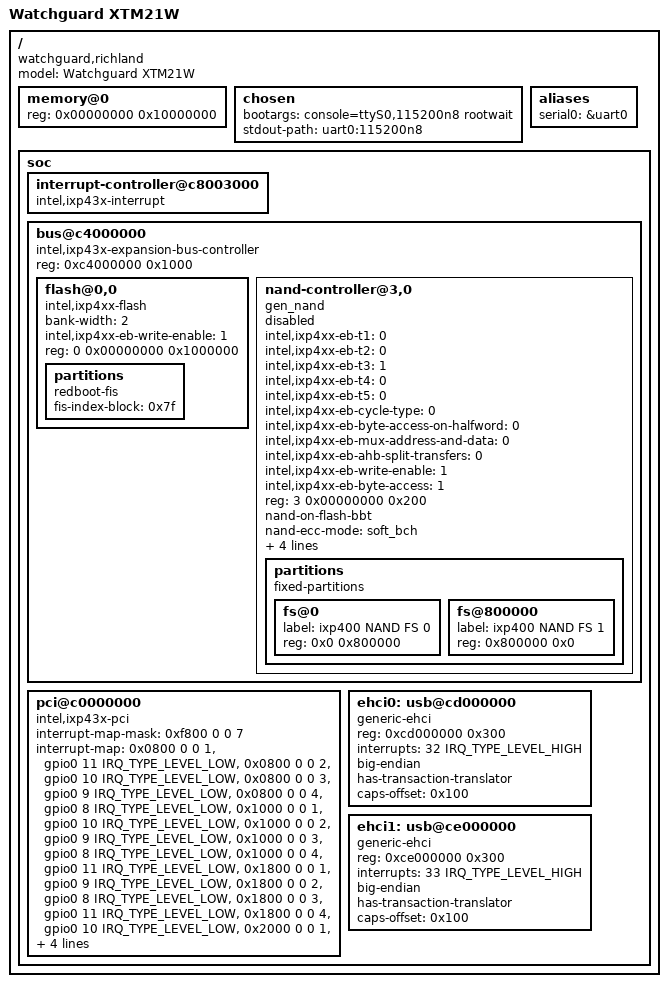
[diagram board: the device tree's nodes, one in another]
// SPDX-License-Identifier: ISC
/*
 * Device Tree file for the Watchguard XTM21-W
 * firewall device.
 */

/dts-v1/;

#include "intel-ixp43x.dtsi"
#include "intel-ixp4xx-reference-design.dtsi"
#include <dt-bindings/input/input.h>

/ {
        model = "Watchguard XTM21W";
        compatible = "watchguard,richland","intel,ixp43x";
        #address-cells = <1>;
        #size-cells = <1>;
        memory@0 {
                /*
                 * The Watchuard XTM21W has 256 MB of memory
                 */
                device_type = "memory";
                reg = <0x00000000 0x10000000>;
        };

        chosen {
                bootargs = "console=ttyS0,115200n8 rootwait";
                stdout-path = "uart0:115200n8";
        };

        aliases {
                serial0 = &uart0;
        };

        soc {
                interrupt-controller@c8003000 {
                        compatible = "intel,ixp43x-interrupt";
                };

                /* TODO: just copied, needs detailed layout for Watchguard Flash and NAND */
                bus@c4000000 {
                        compatible = "intel,ixp43x-expansion-bus-controller", "syscon";
                        /* Uses at least up to 0x230 */
                        reg = <0xc4000000 0x1000>;

                        flash@0,0 {
                                compatible = "intel,ixp4xx-flash", "cfi-flash";
                                bank-width = <2>;
                                /* Enable writes on the expansion bus */
                                intel,ixp4xx-eb-write-enable = <1>;
                                /* 16 MB of Flash mapped in at CS0 */
                                reg = <0 0x00000000 0x1000000>;

                                partitions {
                                        compatible = "redboot-fis";
                                        /* Eraseblock at 0x0fe0000 */
                                        fis-index-block = <0x7f>;
                                };
                        };

                        /* Flash memory defined per-variant */
                        nand-controller@3,0 {
                                /* Some designs have a NAND on CS3 enable it here if present */
                                status = "disabled";

                                /*
                                 * gen_nand needs to be extended and documented to get
                                 * command byte = 1 and address byte = 2 from the device
                                 * tree.
                                 */
                                compatible = "gen_nand";

                                /* Expansion bus set-up */
                                intel,ixp4xx-eb-t1 = <0>;
                                intel,ixp4xx-eb-t2 = <0>;
                                intel,ixp4xx-eb-t3 = <1>; // 1 cycle extra strobe phase
                                intel,ixp4xx-eb-t4 = <0>;
                                intel,ixp4xx-eb-t5 = <0>;
                                intel,ixp4xx-eb-cycle-type = <0>; // Intel cycle type
                                intel,ixp4xx-eb-byte-access-on-halfword = <0>;
                                intel,ixp4xx-eb-mux-address-and-data = <0>;
                                intel,ixp4xx-eb-ahb-split-transfers = <0>;
                                intel,ixp4xx-eb-write-enable = <1>;
                                intel,ixp4xx-eb-byte-access = <1>;

                                /* 512 bytes memory window */
                                reg = <3 0x00000000 0x200>;
                                nand-on-flash-bbt;
                                nand-ecc-mode = "soft_bch";
                                nand-ecc-step-size = <512>;
                                nand-ecc-strength = <4>;
                                nce-gpios = <&gpio0 12 GPIO_ACTIVE_HIGH>; /* NCE */

                                label = "ixp400 NAND";

                                partitions {
                                        compatible = "fixed-partitions";
                                        #address-cells = <1>;
                                        #size-cells = <1>;

                                        fs@0 {
                                                label = "ixp400 NAND FS 0";
                                                reg = <0x0 0x800000>;
                                        };
                                        fs@800000 {
                                                label = "ixp400 NAND FS 1";
                                                reg = <0x800000 0x0>;
                                        };
                                };
                        };
                };

                /* The Linux Kernel Watchguard deployed had the PCI Non-Preftecht Workaround Enabled
                 * So we assume it needed despite the XTM2 being IXP435 ?
                 * PCI: IXP43x Richland silicon detected - PCI Non-Prefetch Workaround Enabled
                 * no difference observed between using compatible ixp42x-pci or ixp43x-pci....
                 * TODO: ixp42x-pci maybe not a good choice, create richland-pci or reduce to 1 slot only as on HW ?
                 */

                pci@c0000000 {
                        compatible = "intel,ixp43x-pci"; /* works wihtout the workaround */
                        status = "ok";

                        /*
                         * Taken from IXDP425 PCI boardfile.
                         * PCI slots on the BIXMB425BD base card.
                         * We have up to 4 slots (IDSEL) with 4 swizzled IRQs.
                         */
                        #interrupt-cells = <1>;
                        interrupt-map-mask = <0xf800 0 0 7>;
                        interrupt-map =
                        /* IDSEL 1 */
                        <0x0800 0 0 1 &gpio0 11 IRQ_TYPE_LEVEL_LOW>, /* INT A on slot 1 is irq 11 */
                        <0x0800 0 0 2 &gpio0 10 IRQ_TYPE_LEVEL_LOW>, /* INT B on slot 1 is irq 10 */
                        <0x0800 0 0 3 &gpio0 9  IRQ_TYPE_LEVEL_LOW>, /* INT C on slot 1 is irq 9 */
                        <0x0800 0 0 4 &gpio0 8  IRQ_TYPE_LEVEL_LOW>, /* INT D on slot 1 is irq 8 */
                        /* IDSEL 2 */
                        <0x1000 0 0 1 &gpio0 10 IRQ_TYPE_LEVEL_LOW>, /* INT A on slot 2 is irq 10 */
                        <0x1000 0 0 2 &gpio0 9  IRQ_TYPE_LEVEL_LOW>, /* INT B on slot 2 is irq 9 */
                        <0x1000 0 0 3 &gpio0 8  IRQ_TYPE_LEVEL_LOW>, /* INT C on slot 2 is irq 8 */
                        <0x1000 0 0 4 &gpio0 11 IRQ_TYPE_LEVEL_LOW>, /* INT D on slot 2 is irq 11 */
                        /* IDSEL 3 */
                        <0x1800 0 0 1 &gpio0 9  IRQ_TYPE_LEVEL_LOW>, /* INT A on slot 3 is irq 9 */
                        <0x1800 0 0 2 &gpio0 8  IRQ_TYPE_LEVEL_LOW>, /* INT B on slot 3 is irq 8 */
                        <0x1800 0 0 3 &gpio0 11 IRQ_TYPE_LEVEL_LOW>, /* INT C on slot 3 is irq 11 */
                        <0x1800 0 0 4 &gpio0 10 IRQ_TYPE_LEVEL_LOW>, /* INT D on slot 3 is irq 10 */
                        /* IDSEL 4 */
                        <0x2000 0 0 1 &gpio0 8  IRQ_TYPE_LEVEL_LOW>, /* INT A on slot 4 is irq 8 */
                        <0x2000 0 0 2 &gpio0 11 IRQ_TYPE_LEVEL_LOW>, /* INT B on slot 4 is irq 11 */
                        <0x2000 0 0 3 &gpio0 10 IRQ_TYPE_LEVEL_LOW>, /* INT C on slot 4 is irq 10 */
                        <0x2000 0 0 4 &gpio0 9  IRQ_TYPE_LEVEL_LOW>; /* INT D on slot 4 is irq 9 */
                };

                /* this used to work on platform code */

                ehci0: usb@cd000000 {
                       compatible = "generic-ehci";
                       reg = <0xcd000000 0x300>;
                       interrupts = <32 IRQ_TYPE_LEVEL_HIGH>;
                       big-endian;
                       has-transaction-translator;
                       caps-offset = <0x100>;
                       status = "ok";
                };

                ehci1: usb@ce000000 {
                       compatible = "generic-ehci";
                       reg = <0xce000000 0x300>;
                       interrupts = <33 IRQ_TYPE_LEVEL_HIGH>;
                       big-endian;
                       has-transaction-translator;
                       caps-offset = <0x100>;
                       status = "ok";
                };

            };
};
